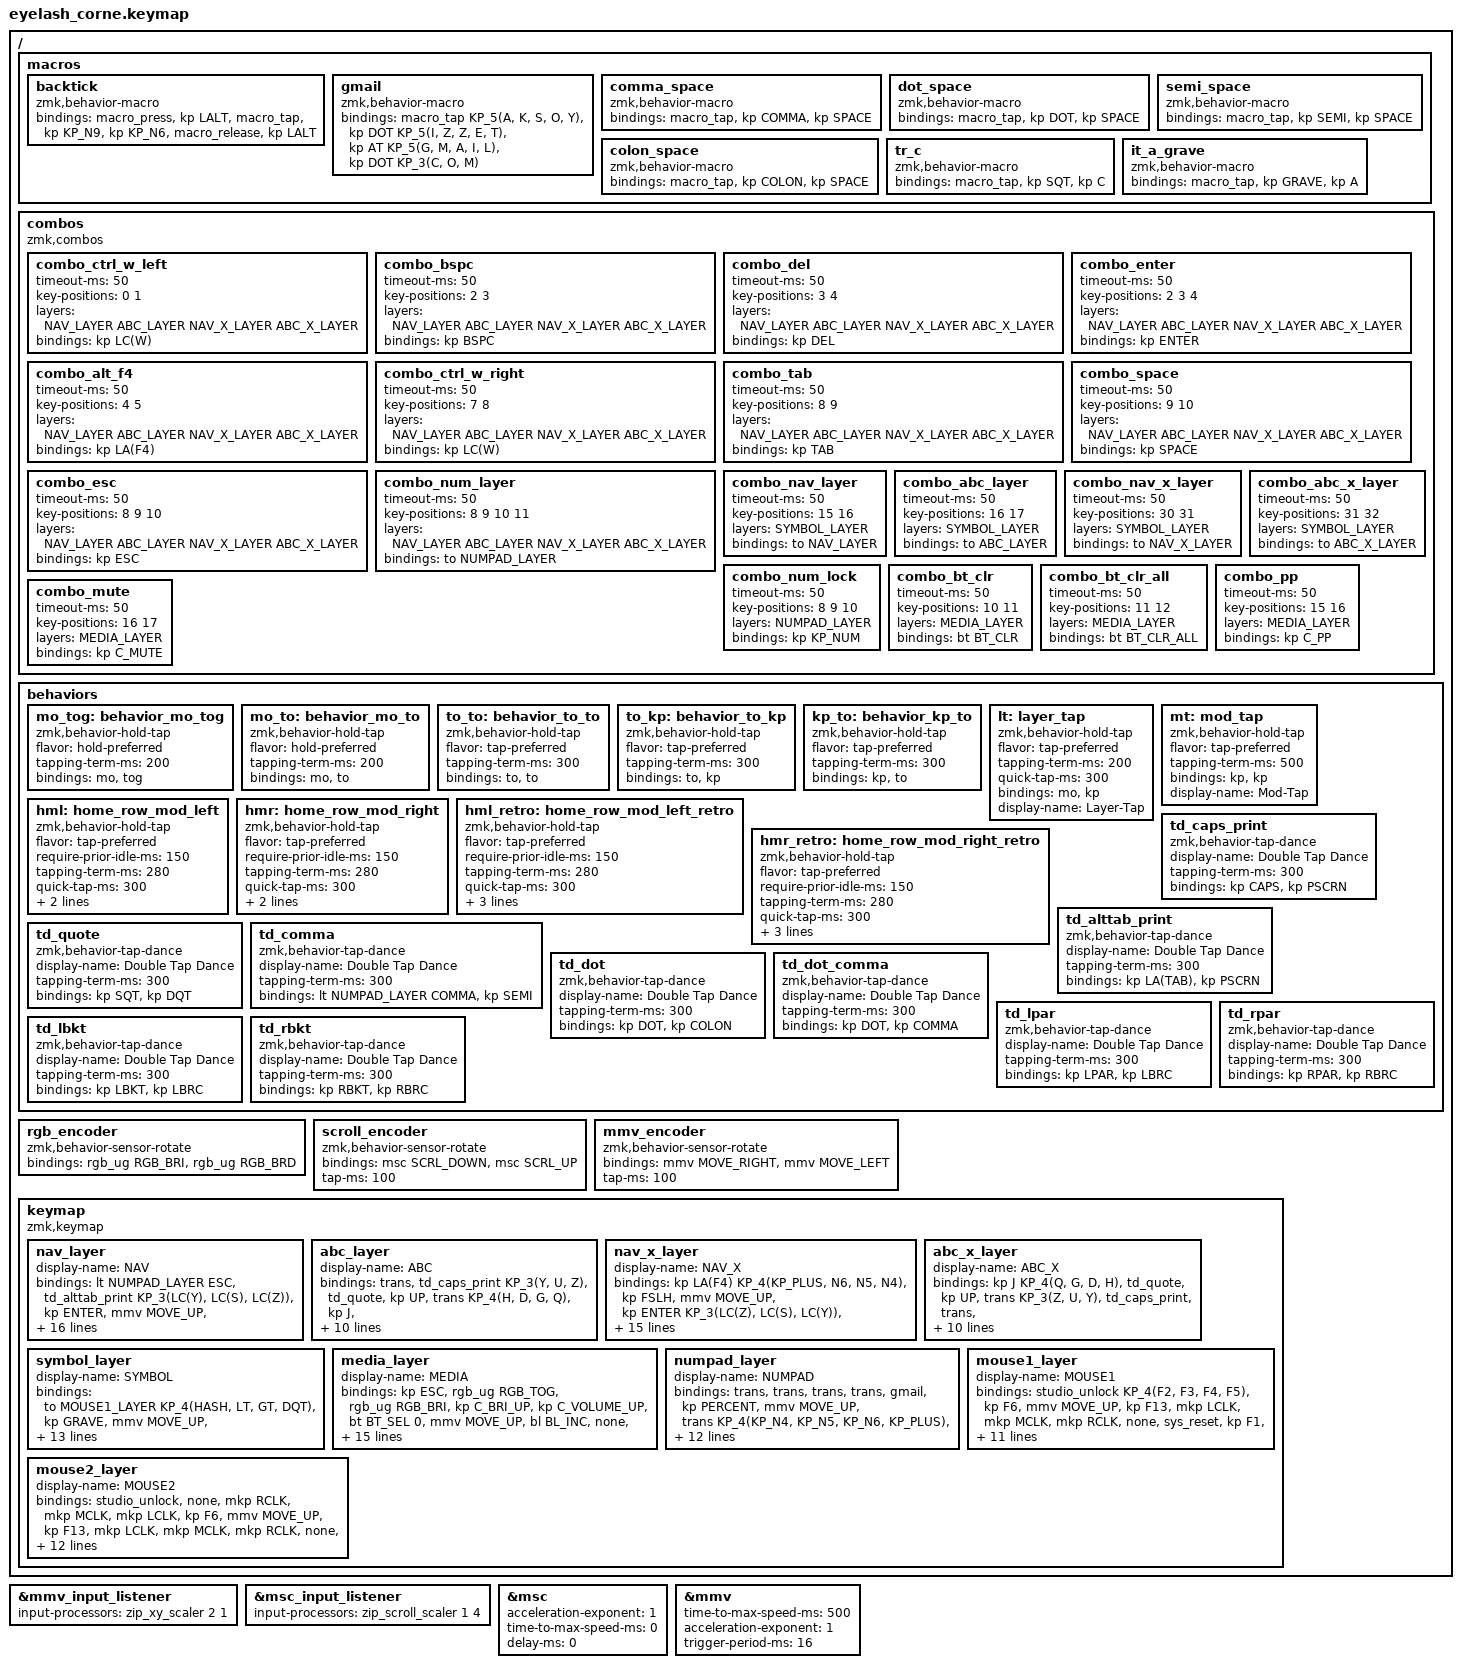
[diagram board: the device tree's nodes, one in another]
#define ZMK_POINTING_DEFAULT_MOVE_VAL 600  // 600
#define ZMK_POINTING_DEFAULT_SCRL_VAL 200  // 10

#include <input/processors.dtsi>
#include <zephyr/dt-bindings/input/input-event-codes.h>
#include <behaviors.dtsi>
#include <dt-bindings/zmk/bt.h>
#include <dt-bindings/zmk/keys.h>
#include <dt-bindings/zmk/outputs.h>
#include <dt-bindings/zmk/pointing.h>
#include <dt-bindings/zmk/rgb.h>
#include <dt-bindings/zmk/backlight.h>


&mmv_input_listener { input-processors = <&zip_xy_scaler 2 1>; };

&msc_input_listener { input-processors = <&zip_scroll_scaler 1 4>; };

&msc {
    acceleration-exponent = <1>;      // 0
    time-to-max-speed-ms = <0>;     // 300
    delay-ms = <0>;                  // 0
};

&mmv {
    time-to-max-speed-ms = <500>;
    acceleration-exponent = <1>;
    trigger-period-ms = <16>;
};

#define NAV_LAYER    0
#define ABC_LAYER    1
#define NAV_X_LAYER  2
#define ABC_X_LAYER  3
#define SYMBOL_LAYER 4
#define MEDIA_LAYER  5
#define NUMPAD_LAYER 6
#define MOUSE1_LAYER 7
#define MOUSE2_LAYER 8 

#define KP_3(kp1, kp2, kp3) &kp kp1  &kp kp2  &kp kp3
#define KP_4(kp1, kp2, kp3, kp4) &kp kp1  &kp kp2  &kp kp3  &kp kp4
#define KP_5(kp1, kp2, kp3, kp4, kp5) &kp kp1  &kp kp2  &kp kp3  &kp kp4  &kp kp5
#define MO_TOG(layer_mo, layer_tog) &mo_tog layer_mo layer_tog   // Macro to apply momentary-layer-on-hold/toggle-layer-on-tap to a specific layer
#define MO_TO(layer_mo, layer_to) &mo_to layer_mo layer_to   // Macro to apply momentary-layer-on-hold/to-layer-on-tap to a specific layer
#define HML_GUI_TO_CTRL_RETRO(lgui, lalt, lshift, lctrl) &hml_retro LGUI lgui  &hml_retro LALT lalt  &hml_retro LSHFT lshift  &hml_retro LCTRL lctrl
#define HML_GUI_TO_CTRL(lgui, lalt, lshift, lctrl) &hml LGUI lgui    &hml LALT lalt     &hml LSHFT lshift  &hml LCTRL lctrl
#define HMR_GUI_TO_CTRL(rgui, lalt, rshift, rctrl) &hmr RGUI rgui    &hmr LALT lalt     &hmr RSHFT rshift  &hmr RCTRL rctrl
#define HML_CTRL_TO_GUI(lctrl, lshift, lalt, lgui) &hml LCTRL lctrl  &hml LSHFT lshift  &hml LALT lalt     &hml LGUI lgui
#define HMR_CTRL_TO_GUI(rctrl, rshift, lalt, rgui) &hmr RCTRL rctrl  &hmr RSHFT rshift  &hmr LALT lalt     &hmr RGUI rgui
#define HMR_CTRL_TO_GUI_MACRO(m1, m2, m3, m4) &m1 &m2 &m3 &m4
#define HMR_GUI_TO_CTRL_RETRO(rgui, lalt, rshift, rctrl) &hmr_retro RGUI rgui    &hmr_retro LALT lalt     &hmr_retro RSHFT rshift  &hmr_retro RCTRL rctrl
#define HMR_CTRL_TO_GUI_RETRO(rctrl, rshift, lalt, rgui) &hmr_retro RCTRL rctrl  &hmr_retro RSHFT rshift  &hmr_retro LALT lalt     &hmr_retro RGUI rgui
// #define TD_HML(mod_key, key_press) &td_hml mod_key key_press key_press   // Macro to apply momentary-layer-on-hold/to-layer-on-tap to a specific layer
// #define TD_DC(single_tap, double_tap) &td_dc single_tap double_tap   // Macro to apply tap dance

/ {
    macros {
        backtick: backtick {
            compatible = "zmk,behavior-macro";
            #binding-cells = <0>;
            bindings
                = <&macro_press &kp LALT>
                , <&macro_tap &kp KP_N9 &kp KP_N6>
                , <&macro_release &kp LALT>
                ;
        };
        gmail: gmail {
            compatible = "zmk,behavior-macro";
            #binding-cells = <0>;
            bindings = <&macro_tap KP_5(A, K, S, O, Y) &kp DOT KP_5(I, Z, Z, E, T) &kp AT KP_5(G, M, A, I, L) &kp DOT KP_3(C, O, M)>;
        };
        comma_space: comma_space {
            compatible = "zmk,behavior-macro";
            #binding-cells = <0>;
            bindings = <&macro_tap &kp COMMA  &kp SPACE>;
        };
        dot_space: dot_space {
            compatible = "zmk,behavior-macro";
            #binding-cells = <0>;
            bindings = <&macro_tap &kp DOT  &kp SPACE>;
        };
        semi_space: semi_space {
            compatible = "zmk,behavior-macro";
            #binding-cells = <0>;
            bindings = <&macro_tap &kp SEMI  &kp SPACE>;
        };
        colon_space: colon_space {
            compatible = "zmk,behavior-macro";
            #binding-cells = <0>;
            bindings = <&macro_tap &kp COLON  &kp SPACE>;
        };
        // Using dead keys with US International layout
        tr_c: tr_c { // ç
            compatible = "zmk,behavior-macro";
            #binding-cells = <0>;
            bindings = <&macro_tap &kp SQT &kp C>;
        };

        it_a_grave: it_a_grave { // à
            compatible = "zmk,behavior-macro";
            #binding-cells = <0>;
            bindings = <&macro_tap &kp GRAVE &kp A>;
        };
    };
    combos {
        compatible = "zmk,combos";
        combo_ctrl_w_left {
            timeout-ms = <50>;
            key-positions = <0 1>;
            layers = <NAV_LAYER ABC_LAYER NAV_X_LAYER ABC_X_LAYER>;
            bindings = <&kp LC(W)>;
        };
        combo_bspc {
            timeout-ms = <50>;
            key-positions = <2 3>;
            layers = <NAV_LAYER ABC_LAYER NAV_X_LAYER ABC_X_LAYER>;
            bindings = <&kp BSPC>;
        };
        combo_del {
            timeout-ms = <50>;
            key-positions = <3 4>;
            layers = <NAV_LAYER ABC_LAYER NAV_X_LAYER ABC_X_LAYER>;
            bindings = <&kp DEL>;
        };
        combo_enter {
            timeout-ms = <50>;
            key-positions = <2 3 4>;
            layers = <NAV_LAYER ABC_LAYER NAV_X_LAYER ABC_X_LAYER>;
            bindings = <&kp ENTER>;
        };
        combo_alt_f4 {
            timeout-ms = <50>;
            key-positions = <4 5>;
            layers = <NAV_LAYER ABC_LAYER NAV_X_LAYER ABC_X_LAYER>;
            bindings = <&kp LA(F4)>;
        };
        combo_ctrl_w_right {
            timeout-ms = <50>;
            key-positions = <7 8>;
            layers = <NAV_LAYER ABC_LAYER NAV_X_LAYER ABC_X_LAYER>;
            bindings = <&kp LC(W)>;
        };
        combo_tab {
            timeout-ms = <50>;
            key-positions = <8 9>;
            layers = <NAV_LAYER ABC_LAYER NAV_X_LAYER ABC_X_LAYER>;
            bindings = <&kp TAB>;
        };
        combo_space {
            timeout-ms = <50>;
            key-positions = <9 10>;
            layers = <NAV_LAYER ABC_LAYER NAV_X_LAYER ABC_X_LAYER>;
            bindings = <&kp SPACE>;
        };
        combo_esc {
            timeout-ms = <50>;
            key-positions = <8 9 10>;
            layers = <NAV_LAYER ABC_LAYER NAV_X_LAYER ABC_X_LAYER>;
            bindings = <&kp ESC>;
        };
        combo_num_layer {
            timeout-ms = <50>;
            key-positions = <8 9 10 11>;
            layers = <NAV_LAYER ABC_LAYER NAV_X_LAYER ABC_X_LAYER>;
            bindings = <&to NUMPAD_LAYER>;
        };
        combo_nav_layer {
            timeout-ms = <50>;
            key-positions = <15 16>;
            layers = <SYMBOL_LAYER>;
            bindings = <&to NAV_LAYER>;
        };
        combo_abc_layer {
            timeout-ms = <50>;
            key-positions = <16 17>;
            layers = <SYMBOL_LAYER>;
            bindings = <&to ABC_LAYER>;
        };
        combo_nav_x_layer {
            timeout-ms = <50>;
            key-positions = <30 31>;
            layers = <SYMBOL_LAYER>;
            bindings = <&to NAV_X_LAYER>;
        };
        combo_abc_x_layer {
            timeout-ms = <50>;
            key-positions = <31 32>;
            layers = <SYMBOL_LAYER>;
            bindings = <&to ABC_X_LAYER>;
        };
        combo_num_lock {
            timeout-ms = <50>;
            key-positions = <8 9 10>;
            layers = <NUMPAD_LAYER>;
            bindings = <&kp KP_NUM>;
        };
        combo_bt_clr {
            timeout-ms = <50>;
            key-positions = <10 11>;
            layers = <MEDIA_LAYER>;
            bindings = <&bt BT_CLR>;
        };
        combo_bt_clr_all {
            timeout-ms = <50>;
            key-positions = <11 12>;
            layers = <MEDIA_LAYER>;
            bindings = <&bt BT_CLR_ALL>;
        };
        combo_pp {
            timeout-ms = <50>;
            key-positions = <15 16>;
            layers = <MEDIA_LAYER>;
            bindings = <&kp C_PP>;
        };
        combo_mute {
            timeout-ms = <50>;
            key-positions = <16 17>;
            layers = <MEDIA_LAYER>;
            bindings = <&kp C_MUTE>;
        };
    };
    behaviors {
        mo_tog: behavior_mo_tog {
            compatible = "zmk,behavior-hold-tap";
            #binding-cells = <2>;
            flavor = "hold-preferred";
            tapping-term-ms = <200>;
            bindings = <&mo>, <&tog>;
        };
        mo_to: behavior_mo_to {
            compatible = "zmk,behavior-hold-tap";
            #binding-cells = <2>;
            flavor = "hold-preferred";
            tapping-term-ms = <200>;
            bindings = <&mo>, <&to>;
        };
        
        to_to: behavior_to_to {
            compatible = "zmk,behavior-hold-tap";
            #binding-cells = <2>;
            flavor = "tap-preferred";
            tapping-term-ms = <300>;
            bindings = <&to>, <&to>;
        };
        
        to_kp: behavior_to_kp {
            compatible = "zmk,behavior-hold-tap";
            #binding-cells = <2>;
            flavor = "tap-preferred";
            tapping-term-ms = <300>;
            bindings = <&to>, <&kp>;
        };

        
        kp_to: behavior_kp_to {
            compatible = "zmk,behavior-hold-tap";
            #binding-cells = <2>;
            flavor = "tap-preferred";
            tapping-term-ms = <300>;
            bindings = <&kp>, <&to>;
        };
        
        lt: layer_tap {
            compatible = "zmk,behavior-hold-tap";
            #binding-cells = <2>;
            flavor = "tap-preferred";
            tapping-term-ms = <200>;
            quick-tap-ms = <300>;
            bindings = <&mo>, <&kp>;
            display-name = "Layer-Tap";
        };
        
        mt: mod_tap {
            compatible = "zmk,behavior-hold-tap";
            #binding-cells = <2>;
            flavor = "tap-preferred";
            tapping-term-ms = <500>;
            bindings = <&kp>, <&kp>;
            display-name = "Mod-Tap";
        };

        hml: home_row_mod_left {
            compatible = "zmk,behavior-hold-tap";
            #binding-cells = <2>;
            flavor = "tap-preferred";
            require-prior-idle-ms = <150>;
            tapping-term-ms = <280>;
            quick-tap-ms = <300>;
            bindings = <&kp>, <&kp>;
            //hold-trigger-key-positions = < ... >; // List of keys on the right side of the keyboard
            hold-trigger-on-release;
        };
        hmr: home_row_mod_right {
            compatible = "zmk,behavior-hold-tap";
            #binding-cells = <2>;
            flavor = "tap-preferred";
            require-prior-idle-ms = <150>;
            tapping-term-ms = <280>;
            quick-tap-ms = <300>;
            bindings = <&kp>, <&kp>;
            //hold-trigger-key-positions = < ... >; // List of keys on the left side of the keyboard
            hold-trigger-on-release;
        };
        hml_retro: home_row_mod_left_retro {
            compatible = "zmk,behavior-hold-tap";
            #binding-cells = <2>;
            flavor = "tap-preferred";
            require-prior-idle-ms = <150>;
            tapping-term-ms = <280>;
            quick-tap-ms = <300>;
            bindings = <&kp>, <&kp>;
            //hold-trigger-key-positions = < ... >; // List of keys on the right side of the keyboard
            hold-trigger-on-release;
            retro-tap;
        };
        hmr_retro: home_row_mod_right_retro {
            compatible = "zmk,behavior-hold-tap";
            #binding-cells = <2>;
            flavor = "tap-preferred";
            require-prior-idle-ms = <150>;
            tapping-term-ms = <280>;
            quick-tap-ms = <300>;
            bindings = <&kp>, <&kp>;
            //hold-trigger-key-positions = < ... >; // List of keys on the left side of the keyboard
            hold-trigger-on-release;
            retro-tap;
        };
        td_caps_print: td_caps_print {
            compatible = "zmk,behavior-tap-dance";
            display-name = "Double Tap Dance";
            #binding-cells = <0>;
            tapping-term-ms = <300>;
            bindings = <&kp CAPS>, <&kp PSCRN>;
        };
        td_alttab_print: td_alttab_print {
            compatible = "zmk,behavior-tap-dance";
            display-name = "Double Tap Dance";
            #binding-cells = <0>;
            tapping-term-ms = <300>;
            bindings = <&kp LA(TAB)>, <&kp PSCRN>;
        };
        td_quote: td_quote {
            compatible = "zmk,behavior-tap-dance";
            display-name = "Double Tap Dance";
            #binding-cells = <0>;
            tapping-term-ms = <300>;
            bindings = <&kp SQT>, <&kp DQT>;
        };
        td_comma: td_comma {
            compatible = "zmk,behavior-tap-dance";
            display-name = "Double Tap Dance";
            #binding-cells = <0>;
            tapping-term-ms = <300>;
            bindings = <&lt NUMPAD_LAYER COMMA>, <&kp SEMI>;
        };
        td_dot: td_dot {
            compatible = "zmk,behavior-tap-dance";
            display-name = "Double Tap Dance";
            #binding-cells = <0>;
            tapping-term-ms = <300>;
            bindings = <&kp DOT>, <&kp COLON>;
        };
        td_dot_comma: td_dot_comma {
            compatible = "zmk,behavior-tap-dance";
            display-name = "Double Tap Dance";
            #binding-cells = <0>;
            tapping-term-ms = <300>;
            bindings = <&kp DOT>, <&kp COMMA>;
        };
        td_lpar: td_lpar {
            compatible = "zmk,behavior-tap-dance";
            display-name = "Double Tap Dance";
            #binding-cells = <0>;
            tapping-term-ms = <300>;
            bindings = <&kp LPAR>, <&kp LBRC>;
        };
        td_rpar: td_rpar {
            compatible = "zmk,behavior-tap-dance";
            display-name = "Double Tap Dance";
            #binding-cells = <0>;
            tapping-term-ms = <300>;
            bindings = <&kp RPAR>, <&kp RBRC>;
        };
        td_lbkt: td_lbkt {
            compatible = "zmk,behavior-tap-dance";
            display-name = "Double Tap Dance";
            #binding-cells = <0>;
            tapping-term-ms = <300>;
            bindings = <&kp LBKT>, <&kp LBRC>;
        };
        td_rbkt: td_rbkt {
            compatible = "zmk,behavior-tap-dance";
            display-name = "Double Tap Dance";
            #binding-cells = <0>;
            tapping-term-ms = <300>;
            bindings = <&kp RBKT>, <&kp RBRC>;
        };
    };

    rgb_encoder: rgb_encoder {
        compatible = "zmk,behavior-sensor-rotate";
        #sensor-binding-cells = <0>;
        bindings = <&rgb_ug RGB_BRI>, <&rgb_ug RGB_BRD>;
    };

    scroll_encoder: scroll_encoder {
        compatible = "zmk,behavior-sensor-rotate";
        #sensor-binding-cells = <0>;
        bindings = <&msc SCRL_DOWN>, <&msc SCRL_UP>;
        tap-ms = <100>;
    };

    mmv_encoder: mmv_encoder {
        compatible = "zmk,behavior-sensor-rotate";
        #sensor-binding-cells = <0>;
        bindings = <&mmv MOVE_RIGHT>, <&mmv MOVE_LEFT>;
        tap-ms = <100>;
    };

    keymap {
        compatible = "zmk,keymap";

        nav_layer {
            display-name = "NAV";
            bindings = <
&lt NUMPAD_LAYER ESC    &td_alttab_print  KP_3(LC(Y), LC(S), LC(Z))   &kp ENTER                      &mmv MOVE_UP                &kp FSLH                   KP_4(N4, N5, N6, KP_PLUS)   &kp LA(F4)
&lt MEDIA_LAYER LC(A)   HML_GUI_TO_CTRL_RETRO(LEFT, DOWN, UP, RIGHT)  &td_comma      &mmv MOVE_LEFT  &mkp LCLK  &mmv MOVE_RIGHT  &td_dot   HMR_CTRL_TO_GUI_RETRO(N1, N2, N3, N0)        &to_kp NAV_LAYER KP_EQUAL
&to_kp ABC_LAYER DEL    HML_CTRL_TO_GUI(LC(X), LC(V), LC(F), LC(C))   &td_lpar   &kp C_MUTE          &mmv MOVE_DOWN              &td_rpar  HMR_GUI_TO_CTRL_RETRO(N7, N8, N9, KP_MINUS)  &kp DEL
                   &lt SYMBOL_LAYER TAB  MO_TO(ABC_LAYER, NAV_LAYER)  &lt MOUSE1_LAYER SPACE             &lt SYMBOL_LAYER ENTER  MO_TO(NUMPAD_LAYER, ABC_LAYER)  &lt MOUSE1_LAYER BSPC
            >;

            sensor-bindings = <&scroll_encoder>;
        };

        abc_layer {
            display-name = "ABC";
            bindings = <
&trans             &td_caps_print  KP_3(Y, U, Z)  &td_quote               &kp UP        &trans             KP_4(H, D, G, Q)  &kp J
&lt MEDIA_LAYER W  HML_GUI_TO_CTRL(A, E, I, O)    &trans       KP_3(LEFT, ENTER, RIGHT) &trans  HMR_CTRL_TO_GUI(R, S, T, N)  &to_kp NAV_LAYER P
&kp LGUI           HML_CTRL_TO_GUI(X, V, F, C)    &trans  &kp SPACE    &kp DOWN         &trans  HMR_GUI_TO_CTRL(L, K, M, B)  &trans
                            &trans  &kp_to LSHFT NAV_LAYER  &trans                      &trans  &trans  &lt MOUSE1_LAYER BSPC
            >;

            sensor-bindings = <&scroll_encoder>;
        };

        nav_x_layer {
            display-name = "NAV_X";
            bindings = <
&kp LA(F4)                            KP_4(KP_PLUS, N6, N5, N4)    &kp FSLH                      &mmv MOVE_UP                    &kp ENTER     KP_3(LC(Z), LC(S), LC(Y))   &td_alttab_print   &lt NUMPAD_LAYER ESC
&lt MEDIA_LAYER KP_EQUAL  HML_GUI_TO_CTRL_RETRO(N0, N3, N2, N1)    &td_dot       &mmv MOVE_LEFT  &mkp LCLK  &mmv MOVE_RIGHT      &td_comma     HMR_CTRL_TO_GUI_RETRO(LEFT, UP, DOWN, RIGHT)   &to_kp NAV_X_LAYER LC(A)
&to_kp ABC_X_LAYER DEL      HML_CTRL_TO_GUI(N7, N8, N9, KP_MINUS)  &td_rpar  &kp C_MUTE          &mmv MOVE_DOWN                  &td_lpar  HMR_GUI_TO_CTRL_RETRO(LC(C), LC(F), LC(V), LC(X))  &kp DEL
                                            &trans  MO_TO(ABC_X_LAYER, NAV_X_LAYER)  &trans                &trans  MO_TO(NUMPAD_LAYER, ABC_X_LAYER)  &trans
            >;

            sensor-bindings = <&scroll_encoder>;
        };

        abc_x_layer {
            display-name = "ABC_X";
            bindings = <
&kp J                         KP_4(Q, G, D, H)  &td_quote            &kp UP           &trans  KP_3(Z, U, Y) &td_caps_print  &trans
&lt MEDIA_LAYER P  HML_GUI_TO_CTRL(N, T, S, R)  &trans       KP_3(LEFT, ENTER, RIGHT) &trans  HMR_CTRL_TO_GUI(O, I, E, A)   &to_kp NAV_X_LAYER W
&trans             HML_CTRL_TO_GUI(B, M, K, L)  &trans  &kp SPACE    &kp DOWN         &trans  HMR_GUI_TO_CTRL(C, F, V, X)   &kp LGUI 
                            &trans  &kp_to LSHFT NAV_X_LAYER  &trans                  &trans  &trans  &lt MOUSE1_LAYER BSPC
            >;

            sensor-bindings = <&scroll_encoder>;
        };


        symbol_layer {
            display-name = "SYMBOL";
            bindings = <
&to MOUSE1_LAYER                   KP_4(HASH,  LT,    GT,   DQT)   &kp GRAVE                         &mmv MOVE_UP                            &kp BSLH                              KP_4(DOLLAR, QMARK, AT_SIGN, CARET)          &none
&to NAV_X_LAYER        HML_GUI_TO_CTRL(UNDER, MINUS, PLUS, EQUAL)  &to ABC_X_LAYER             &mmv MOVE_LEFT  &mkp LCLK  &mmv MOVE_RIGHT    &kp EXCL   HMR_CTRL_TO_GUI_MACRO(semi_space, comma_space, dot_space, colon_space)  &kp PERCENT
&to_kp NAV_LAYER K_CMENU  HML_CTRL_TO_GUI(DOT, FSLH, ASTRK, LBRC)  &td_lbkt   &kp C_MUTE             &mmv MOVE_DOWN                          &td_rbkt                      HMR_GUI_TO_CTRL(RBRC, AMPS, PIPE, TILDE)             &trans
                                                           &trans  &trans  &trans                                                    &trans  &trans  &trans
            >;
            sensor-bindings = <&scroll_encoder>;
        };

        media_layer {
            display-name = "MEDIA";
            bindings = <
&kp ESC       &rgb_ug RGB_TOG &rgb_ug RGB_BRI  &kp C_BRI_UP  &kp C_VOLUME_UP                   &bt BT_SEL 0                      &mmv MOVE_UP                &bl BL_INC  &none          &rgb_ug RGB_EFF  &none      &none      &none
&bt BT_SEL 4           HML_GUI_TO_CTRL(C_PREV, C_RW, C_FF, C_NEXT)                             &bt BT_SEL 1      &mmv MOVE_LEFT  &mkp LCLK  &mmv MOVE_RIGHT  &bl BL_TOG        HMR_CTRL_TO_GUI(HOME, PG_UP, PG_DN, END)        &none
&bt BT_SEL 3  &rgb_ug RGB_COLOR_HSB(0,0,10)  &rgb_ug RGB_BRD  &kp C_BRI_DN  &kp C_VOLUME_DOWN  &bt BT_SEL 2   &to MOUSE1_LAYER   &mmv MOVE_DOWN              &bl BL_DEC  &hmr RGUI INS  &rgb_ug RGB_EFR  &kp RSHFT  &kp RCTRL  &trans
                                                                                       &trans  &trans  &trans                                         &trans &trans &trans
            >;

            sensor-bindings = <&inc_dec_kp C_VOLUME_UP C_VOLUME_DOWN>;
        };
        
        numpad_layer {
            display-name = "NUMPAD";
            bindings = <
&trans    &trans      &trans      &trans      &gmail  &kp PERCENT                  &mmv MOVE_UP                 &trans                    KP_4(KP_N4, KP_N5, KP_N6, KP_PLUS)    &kp ASTRK
&kp EXCL  HML_GUI_TO_CTRL(UNDER, MINUS, PLUS, EQUAL)  &kp DOLLAR   &mmv MOVE_LEFT  &mkp LCLK  &mmv MOVE_RIGHT   &td_dot_comma  HMR_CTRL_TO_GUI(KP_N1, KP_N2, KP_N3, KP_N0)      &kp KP_EQUAL
&trans    HML_CTRL_TO_GUI(QMARK, FSLH, ASTRK, LBRC)   &trans   &kp C_MUTE          &mmv MOVE_DOWN               &td_lbkt       HMR_GUI_TO_CTRL(KP_N7, KP_N8, KP_N9, KP_MINUS)   &td_rbkt
                                              &trans  &trans  &trans                                    &trans  &trans  &trans
            >;
            sensor-bindings = <&scroll_encoder>;
        };
        
        mouse1_layer {
            display-name = "MOUSE1";
            bindings = <
&studio_unlock                         KP_4(F2, F3, F4, F5)                    &kp F6                               &mmv MOVE_UP                     &kp F13  &mkp LCLK       &mkp MCLK       &mkp RCLK       &none            &sys_reset
&kp F1          &msc SCRL_LEFT  &msc SCRL_DOWN  &msc SCRL_UP  &msc SCRL_RIGHT  &kp F7               &mmv MOVE_LEFT  &mkp LCLK       &mmv MOVE_RIGHT  &kp F14  &mmv MOVE_LEFT  &mmv MOVE_UP    &mmv MOVE_DOWN  &mmv MOVE_RIGHT  &none
&bootloader                 HML_CTRL_TO_GUI(F9, F10, F11, F12)                 &kp F8  &kp C_MUTE                   &mmv MOVE_DOWN                   &kp F15  &msc SCRL_LEFT  &msc SCRL_UP    &msc SCRL_DOWN  &msc SCRL_RIGHT  &bootloader        
                                                                     &kp LALT  &trans  &mo MOUSE2_LAYER                                                 &trans &trans &kp DEL
            >;

            sensor-bindings = <&mmv_encoder>;
        };
        
        mouse2_layer {
            display-name = "MOUSE2";
            bindings = <
&studio_unlock        &none  &mkp RCLK       &mkp MCLK      &mkp LCLK        &kp F6                               &mmv MOVE_UP                     &kp F13  &mkp LCLK       &mkp MCLK       &mkp RCLK       &none            &sys_reset
&kp F1       &mmv MOVE_LEFT  &mmv MOVE_DOWN  &mmv MOVE_UP   &mmv MOVE_RIGHT  &kp F7               &mmv MOVE_LEFT  &mkp LCLK       &mmv MOVE_RIGHT  &kp F14  &mmv MOVE_LEFT  &mmv MOVE_UP    &mmv MOVE_DOWN  &mmv MOVE_RIGHT  &none
&bootloader         HML_CTRL_TO_GUI(F9, F10, F11, F12)                       &kp F8  &kp C_MUTE                   &mmv MOVE_DOWN                   &kp F15  &msc SCRL_LEFT  &msc SCRL_UP    &msc SCRL_DOWN  &msc SCRL_RIGHT  &bootloader        
                                                                   &kp LALT  &trans  &trans                                                 &trans &trans &kp DEL
            >;

            sensor-bindings = <&mmv_encoder>;
        };
        
    };
};
